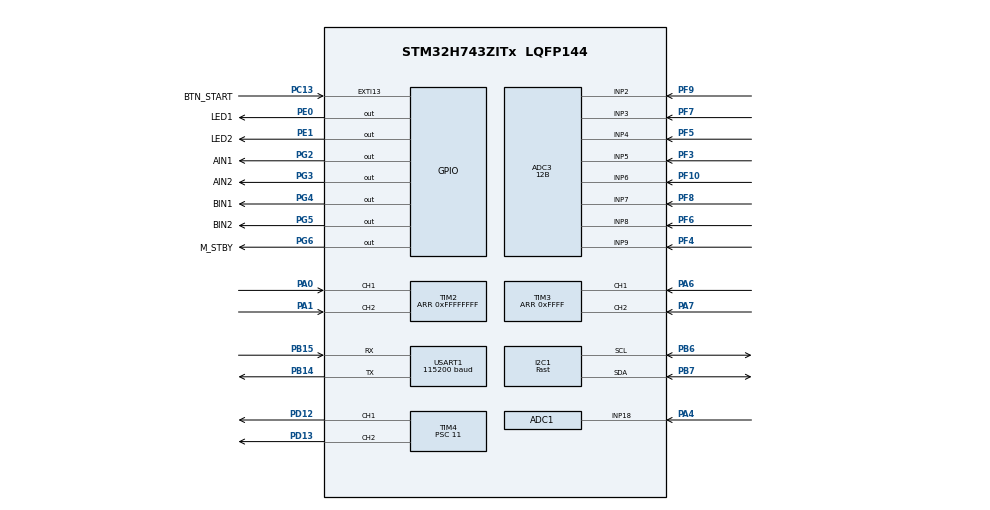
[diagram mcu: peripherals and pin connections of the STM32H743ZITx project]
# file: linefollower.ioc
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ADC1.Channel-1\#ChannelRegularConversion=ADC_CHANNEL_18
ADC1.NbrOfConversionFlag=1
ADC1.OffsetNumber-1\#ChannelRegularConversion=ADC_OFFSET_NONE
ADC1.OffsetSignedSaturation-1\#ChannelRegularConversion=DISABLE
ADC1.Rank-1\#ChannelRegularConversion=1
ADC1.Resolution=ADC_RESOLUTION_12B
ADC1.SamplingTime-1\#ChannelRegularConversion=ADC_SAMPLETIME_810CYCLES_5
ADC1.master=1
ADC3.Channel-0\#ChannelRegularConversion=ADC_CHANNEL_5
ADC3.Channel-1\#ChannelRegularConversion=ADC_CHANNEL_9
ADC3.Channel-2\#ChannelRegularConversion=ADC_CHANNEL_4
ADC3.Channel-3\#ChannelRegularConversion=ADC_CHANNEL_8
ADC3.Channel-4\#ChannelRegularConversion=ADC_CHANNEL_3
ADC3.Channel-5\#ChannelRegularConversion=ADC_CHANNEL_7
ADC3.Channel-6\#ChannelRegularConversion=ADC_CHANNEL_2
ADC3.Channel-7\#ChannelRegularConversion=ADC_CHANNEL_6
ADC3.ConversionDataManagement=ADC_CONVERSIONDATA_DMA_CIRCULAR
ADC3.EOCSelection=ADC_EOC_SEQ_CONV
ADC3.ExternalTrigConv=ADC_EXTERNALTRIG_T6_TRGO
ADC3.NbrOfConversion=8
ADC3.NbrOfConversionFlag=1
ADC3.OffsetNumber-0\#ChannelRegularConversion=ADC_OFFSET_NONE
ADC3.OffsetNumber-1\#ChannelRegularConversion=ADC_OFFSET_NONE
ADC3.OffsetNumber-2\#ChannelRegularConversion=ADC_OFFSET_NONE
ADC3.OffsetNumber-3\#ChannelRegularConversion=ADC_OFFSET_NONE
ADC3.OffsetNumber-4\#ChannelRegularConversion=ADC_OFFSET_NONE
ADC3.OffsetNumber-5\#ChannelRegularConversion=ADC_OFFSET_NONE
ADC3.OffsetNumber-6\#ChannelRegularConversion=ADC_OFFSET_NONE
ADC3.OffsetNumber-7\#ChannelRegularConversion=ADC_OFFSET_NONE
ADC3.OffsetSignedSaturation-0\#ChannelRegularConversion=DISABLE
ADC3.Rank-0\#ChannelRegularConversion=1
ADC3.Rank-1\#ChannelRegularConversion=2
ADC3.Rank-2\#ChannelRegularConversion=3
ADC3.Rank-3\#ChannelRegularConversion=4
ADC3.Rank-4\#ChannelRegularConversion=5
ADC3.Rank-5\#ChannelRegularConversion=6
ADC3.Rank-6\#ChannelRegularConversion=7
ADC3.Rank-7\#ChannelRegularConversion=8
ADC3.Resolution=ADC_RESOLUTION_12B
ADC3.SamplingTime-0\#ChannelRegularConversion=ADC_SAMPLETIME_387CYCLES_5
ADC3.SamplingTime-1\#ChannelRegularConversion=ADC_SAMPLETIME_387CYCLES_5
ADC3.SamplingTime-2\#ChannelRegularConversion=ADC_SAMPLETIME_387CYCLES_5
ADC3.SamplingTime-3\#ChannelRegularConversion=ADC_SAMPLETIME_387CYCLES_5
ADC3.SamplingTime-4\#ChannelRegularConversion=ADC_SAMPLETIME_387CYCLES_5
ADC3.SamplingTime-5\#ChannelRegularConversion=ADC_SAMPLETIME_387CYCLES_5
ADC3.SamplingTime-6\#ChannelRegularConversion=ADC_SAMPLETIME_387CYCLES_5
ADC3.SamplingTime-7\#ChannelRegularConversion=ADC_SAMPLETIME_387CYCLES_5
Bdma.ADC3.0.Direction=DMA_PERIPH_TO_MEMORY
Bdma.ADC3.0.EventEnable=DISABLE
Bdma.ADC3.0.Instance=BDMA_Channel0
Bdma.ADC3.0.MemDataAlignment=DMA_MDATAALIGN_HALFWORD
Bdma.ADC3.0.MemInc=DMA_MINC_ENABLE
Bdma.ADC3.0.Mode=DMA_CIRCULAR
Bdma.ADC3.0.PeriphDataAlignment=DMA_PDATAALIGN_HALFWORD
Bdma.ADC3.0.PeriphInc=DMA_PINC_DISABLE
Bdma.ADC3.0.Polarity=HAL_DMAMUX_REQ_GEN_RISING
Bdma.ADC3.0.Priority=DMA_PRIORITY_LOW
Bdma.ADC3.0.RequestNumber=1
Bdma.ADC3.0.SignalID=NONE
Bdma.ADC3.0.SyncEnable=DISABLE
Bdma.ADC3.0.SyncPolarity=HAL_DMAMUX_SYNC_NO_EVENT
Bdma.ADC3.0.SyncRequestNumber=1
Bdma.ADC3.0.SyncSignalID=NONE
Bdma.Request0=ADC3
Bdma.RequestsNb=1
CORTEX_M7.AccessPermission_S-Cortex_Memory_Protection_Unit_Region1_Settings_S=MPU_REGION_FULL_ACCESS
CORTEX_M7.AccessPermission_Spec=MPU_REGION_NO_ACCESS
CORTEX_M7.BaseAddress_S-Cortex_Memory_Protection_Unit_Region1_Settings_S=0x38000000
CORTEX_M7.BaseAddress_Spec=0x0
CORTEX_M7.CPU_DCache=Enabled
CORTEX_M7.CPU_ICache=Enabled
CORTEX_M7.DisableExec_S-Cortex_Memory_Protection_Unit_Region1_Settings_S=MPU_INSTRUCTION_ACCESS_DISABLE
CORTEX_M7.DisableExec_Spec=MPU_INSTRUCTION_ACCESS_ENABLE
CORTEX_M7.Enable_S-Cortex_Memory_Protection_Unit_Region1_Settings_S=MPU_REGION_ENABLE
CORTEX_M7.IsShareable_Spec=MPU_ACCESS_NOT_SHAREABLE
CORTEX_M7.Size_S-Cortex_Memory_Protection_Unit_Region1_Settings_S=MPU_REGION_SIZE_64KB
CORTEX_M7.Size_Spec=MPU_REGION_SIZE_4GB
CORTEX_M7.SubRegionDisable_Spec=0x87
CORTEX_M7.TypeExtField_S-Cortex_Memory_Protection_Unit_Region1_Settings_S=MPU_TEX_LEVEL1
CORTEX_M7.TypeExtField_Spec=MPU_TEX_LEVEL0
CORTEX_M7.default_mode_Activation=1
Dma.Request0=USART1_RX
Dma.Request1=USART1_TX
Dma.USART1_RX.0.Direction=DMA_PERIPH_TO_MEMORY
Dma.USART1_RX.0.EventEnable=DISABLE
Dma.USART1_RX.0.FIFOMode=DMA_FIFOMODE_DISABLE
Dma.USART1_RX.0.Instance=DMA1_Stream0
Dma.USART1_RX.0.MemDataAlignment=DMA_MDATAALIGN_BYTE
Dma.USART1_RX.0.MemInc=DMA_MINC_ENABLE
Dma.USART1_RX.0.Mode=DMA_CIRCULAR
Dma.USART1_RX.0.PeriphDataAlignment=DMA_PDATAALIGN_BYTE
Dma.USART1_RX.0.PeriphInc=DMA_PINC_DISABLE
Dma.USART1_RX.0.Polarity=HAL_DMAMUX_REQ_GEN_RISING
Dma.USART1_RX.0.Priority=DMA_PRIORITY_LOW
Dma.USART1_RX.0.RequestNumber=1
Dma.USART1_RX.0.SignalID=NONE
Dma.USART1_RX.0.SyncEnable=DISABLE
Dma.USART1_RX.0.SyncPolarity=HAL_DMAMUX_SYNC_NO_EVENT
Dma.USART1_RX.0.SyncRequestNumber=1
Dma.USART1_RX.0.SyncSignalID=NONE
Dma.USART1_TX.1.Direction=DMA_MEMORY_TO_PERIPH
Dma.USART1_TX.1.EventEnable=DISABLE
Dma.USART1_TX.1.FIFOMode=DMA_FIFOMODE_DISABLE
Dma.USART1_TX.1.Instance=DMA1_Stream1
Dma.USART1_TX.1.MemDataAlignment=DMA_MDATAALIGN_BYTE
Dma.USART1_TX.1.MemInc=DMA_MINC_ENABLE
Dma.USART1_TX.1.Mode=DMA_NORMAL
Dma.USART1_TX.1.PeriphDataAlignment=DMA_PDATAALIGN_BYTE
Dma.USART1_TX.1.PeriphInc=DMA_PINC_DISABLE
Dma.USART1_TX.1.Polarity=HAL_DMAMUX_REQ_GEN_RISING
Dma.USART1_TX.1.Priority=DMA_PRIORITY_LOW
Dma.USART1_TX.1.RequestNumber=1
Dma.USART1_TX.1.SignalID=NONE
Dma.USART1_TX.1.SyncEnable=DISABLE
Dma.USART1_TX.1.SyncPolarity=HAL_DMAMUX_SYNC_NO_EVENT
Dma.USART1_TX.1.SyncRequestNumber=1
Dma.USART1_TX.1.SyncSignalID=NONE
I2C1.I2C_Rise_Time=100
I2C1.I2C_Speed_Mode=I2C_Fast
I2C1.Timing=0x10B01F67
Mcu.Family=STM32H7
Mcu.Name=STM32H743ZITx
Mcu.Package=LQFP144
NVIC.BDMA_Channel0_IRQn=true\:2\:0\:true\:false\:true\:false\:true\:true
NVIC.DMA1_Stream0_IRQn=true\:5\:0\:true\:false\:true\:false\:true\:true
NVIC.DMA1_Stream1_IRQn=true\:5\:0\:true\:false\:true\:false\:true\:true
NVIC.EXTI15_10_IRQn=true\:7\:0\:true\:false\:true\:true\:true\:true
NVIC.I2C1_ER_IRQn=true\:6\:0\:true\:false\:true\:true\:true\:true
NVIC.I2C1_EV_IRQn=true\:6\:0\:true\:false\:true\:true\:true\:true
NVIC.PriorityGroup=NVIC_PRIORITYGROUP_4
NVIC.TIM6_DAC_IRQn=true\:1\:0\:true\:false\:true\:true\:true\:true
NVIC.USART1_IRQn=true\:5\:0\:true\:false\:true\:true\:true\:true
PA0.Signal=S_TIM2_CH1_ETR
PA1.Signal=S_TIM2_CH2
PA13\ (JTMS/SWDIO).Mode=Trace_Asynchronous_SW
PA13\ (JTMS/SWDIO).Signal=DEBUG_JTMS-SWDIO
PA14\ (JTCK/SWCLK).Mode=Trace_Asynchronous_SW
PA14\ (JTCK/SWCLK).Signal=DEBUG_JTCK-SWCLK
PA4.Signal=ADCx_INP18
PA6.Signal=S_TIM3_CH1
PA7.Signal=S_TIM3_CH2
PB14.Mode=Asynchronous
PB14.Signal=USART1_TX
PB15.Mode=Asynchronous
PB15.Signal=USART1_RX
PB3\ (JTDO/TRACESWO).Mode=Trace_Asynchronous_SW
PB3\ (JTDO/TRACESWO).Signal=DEBUG_JTDO-SWO
PB6.Mode=I2C
PB6.Signal=I2C1_SCL
PB7.Mode=I2C
PB7.Signal=I2C1_SDA
PC13.GPIO_Label=BTN_START
PC13.GPIO_ModeDefaultEXTI=GPIO_MODE_IT_FALLING
PC13.GPIO_PuPd=GPIO_PULLUP
PC13.Signal=GPXTI13
PD12.Signal=S_TIM4_CH1
PD13.Signal=S_TIM4_CH2
PE0.GPIO_Label=LED1
PE0.Signal=GPIO_Output
PE1.GPIO_Label=LED2
PE1.Signal=GPIO_Output
PF10.Mode=IN6-Single-Ended
PF10.Signal=ADC3_INP6
PF3.Mode=IN5-Single-Ended
PF3.Signal=ADC3_INP5
PF4.Mode=IN9-Single-Ended
PF4.Signal=ADC3_INP9
PF5.Mode=IN4-Single-Ended
PF5.Signal=ADC3_INP4
PF6.Mode=IN8-Single-Ended
PF6.Signal=ADC3_INP8
PF7.Mode=IN3-Single-Ended
PF7.Signal=ADC3_INP3
PF8.Mode=IN7-Single-Ended
PF8.Signal=ADC3_INP7
PF9.Mode=IN2-Single-Ended
PF9.Signal=ADC3_INP2
PG2.GPIO_Label=AIN1
PG2.Signal=GPIO_Output
PG3.GPIO_Label=AIN2
PG3.Signal=GPIO_Output
PG4.GPIO_Label=BIN1
PG4.Signal=GPIO_Output
PG5.GPIO_Label=BIN2
PG5.Signal=GPIO_Output
PG6.GPIO_Label=M_STBY
PG6.Signal=GPIO_Output
PH0-OSC_IN\ (PH0).Mode=HSE-External-Oscillator
PH0-OSC_IN\ (PH0).Signal=RCC_OSC_IN
PH1-OSC_OUT\ (PH1).Mode=HSE-External-Oscillator
PH1-OSC_OUT\ (PH1).Signal=RCC_OSC_OUT
ProjectManager.HeapSize=0x200
ProjectManager.StackSize=0x400
ProjectManager.TargetToolchain=STM32CubeIDE
RCC.ADCFreq_Value=36000000
RCC.APB1Freq_Value=120000000
RCC.APB2Freq_Value=120000000
RCC.APB3Freq_Value=120000000
RCC.APB4Freq_Value=120000000
RCC.CortexFreq_Value=480000000
RCC.D1PPRE=RCC_APB3_DIV2
RCC.D2PPRE1=RCC_APB1_DIV2
RCC.D2PPRE2=RCC_APB2_DIV2
RCC.D3PPRE=RCC_APB4_DIV2
RCC.DIVM1=5
RCC.DIVM2=5
RCC.DIVN1=192
RCC.DIVN2=72
RCC.DIVP2=10
RCC.HCLKFreq_Value=240000000
RCC.HPRE=RCC_HCLK_DIV2
RCC.HSE_VALUE=25000000
RCC.PLL2FRACN=0
RCC.PLL3FRACN=0
RCC.PLLFRACN=0
RCC.PLLSourceVirtual=RCC_PLLSOURCE_HSE
RCC.SYSCLKFreq_VALUE=480000000
RCC.SYSCLKSource=RCC_SYSCLKSOURCE_PLLCLK
RCC.USBFreq_Value=480000000
SH.ADCx_INP18.0=ADC1_INP18,IN18-Single-Ended
SH.S_TIM2_CH1_ETR.0=TIM2_CH1,Encoder_Interface
SH.S_TIM2_CH2.0=TIM2_CH2,Encoder_Interface
SH.S_TIM3_CH1.0=TIM3_CH1,Encoder_Interface
SH.S_TIM3_CH2.0=TIM3_CH2,Encoder_Interface
SH.S_TIM4_CH1.0=TIM4_CH1,PWM Generation1 CH1
SH.S_TIM4_CH2.0=TIM4_CH2,PWM Generation2 CH2
TIM2.EncoderMode=TIM_ENCODERMODE_TI12
TIM2.IC1Filter=6
TIM2.IC2Filter=6
TIM2.Period=0xFFFFFFFF
TIM3.EncoderMode=TIM_ENCODERMODE_TI12
TIM3.IC1Filter=6
TIM3.IC2Filter=6
TIM3.Period=0xFFFF
TIM4.AutoReloadPreload=TIM_AUTORELOAD_PRELOAD_ENABLE
TIM4.Channel-PWM\ Generation1\ CH1=TIM_CHANNEL_1
TIM4.Channel-PWM\ Generation2\ CH2=TIM_CHANNEL_2
TIM4.OCFastMode_PWM-PWM\ Generation1\ CH1=TIM_OCFAST_ENABLE
TIM4.OCFastMode_PWM-PWM\ Generation2\ CH2=TIM_OCFAST_ENABLE
TIM4.Period=999
TIM4.Prescaler=11
TIM6.Period=999
TIM6.Prescaler=239
TIM6.TIM_MasterOutputTrigger=TIM_TRGO_UPDATE
USART1.BaudRate=115200
USART1.VirtualMode-Asynchronous=VM_ASYNC
VP_MEMORYMAP_VS_MEMORYMAP.Mode=CurAppReg
VP_TIM4_VS_ClockSourceINT.Mode=Internal
VP_TIM6_VS_ClockSourceINT.Mode=Enable_Timer
board=custom

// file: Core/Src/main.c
/* USER CODE BEGIN Header */
/**
  ******************************************************************************
  * @file           : main.c
  * @brief          : Main program body
  ******************************************************************************
  * @attention
  *
  * Copyright (c) 2026 STMicroelectronics.
  * All rights reserved.
  *
  * This software is licensed under terms that can be found in the LICENSE file
  * in the root directory of this software component.
  * If no LICENSE file comes with this software, it is provided AS-IS.
  *
  ******************************************************************************
  */
/* USER CODE END Header */
#include "main.h"
#include "adc.h"
#include "bdma.h"
#include "dma.h"
#include "i2c.h"
#include "memorymap.h"
#include "tim.h"
#include "usart.h"
#include "gpio.h"

/* USER CODE BEGIN PV */
/* ADC3 results, SENS1..SENS8. Stored at the start of RAM_D3 (0x38000000),
   the only RAM the BDMA can reach. MPU makes this area non-cacheable. */
#define ADC3_BUF ((volatile uint16_t *)0x38000000UL)
/* USER CODE END PV */

void SystemClock_Config(void);
void PeriphCommonClock_Config(void);
static void MPU_Config(void);

int main(void)
{

  /* MPU Configuration--------------------------------------------------------*/
  MPU_Config();

  /* Enable the CPU Cache */

  /* Enable I-Cache---------------------------------------------------------*/
  SCB_EnableICache();

  /* Enable D-Cache---------------------------------------------------------*/
  SCB_EnableDCache();

  /* MCU Configuration--------------------------------------------------------*/

  /* Reset of all peripherals, Initializes the Flash interface and the Systick. */
  HAL_Init();

  /* Configure the system clock */
  SystemClock_Config();

  /* Configure the peripherals common clocks */
  PeriphCommonClock_Config();

  /* Initialize all configured peripherals */
  MX_GPIO_Init();
  MX_DMA_Init();
  MX_BDMA_Init();
  MX_USART1_UART_Init();
  MX_ADC1_Init();
  MX_I2C1_Init();
  MX_TIM2_Init();
  MX_TIM3_Init();
  MX_TIM4_Init();
  MX_ADC3_Init();
  MX_TIM6_Init();
  /* USER CODE BEGIN 2 */
  HAL_ADCEx_Calibration_Start(&hadc3, ADC_CALIB_OFFSET, ADC_SINGLE_ENDED); /* calibrate once at start-up */
  HAL_ADC_Start_DMA(&hadc3, (uint32_t *)ADC3_BUF, 8);  /* arm ADC3: 8 results per scan, BDMA circular */
  HAL_TIM_Base_Start_IT(&htim6);                        /* start the 1 kHz tick; it also triggers each ADC3 scan */
  /* USER CODE END 2 */

  /* Infinite loop */
  while (1)
  {

  }
}

void SystemClock_Config(void)
{
  RCC_OscInitTypeDef RCC_OscInitStruct = {0};
  RCC_ClkInitTypeDef RCC_ClkInitStruct = {0};

  /** Supply configuration update enable
  */
  HAL_PWREx_ConfigSupply(PWR_LDO_SUPPLY);

  /** Configure the main internal regulator output voltage
  */
  __HAL_PWR_VOLTAGESCALING_CONFIG(PWR_REGULATOR_VOLTAGE_SCALE0);

  while(!__HAL_PWR_GET_FLAG(PWR_FLAG_VOSRDY)) {}

  /** Initializes the RCC Oscillators according to the specified parameters
  * in the RCC_OscInitTypeDef structure.
  */
  RCC_OscInitStruct.OscillatorType = RCC_OSCILLATORTYPE_HSE;
  RCC_OscInitStruct.HSEState = RCC_HSE_ON;
  RCC_OscInitStruct.PLL.PLLState = RCC_PLL_ON;
  RCC_OscInitStruct.PLL.PLLSource = RCC_PLLSOURCE_HSE;
  RCC_OscInitStruct.PLL.PLLM = 5;
  RCC_OscInitStruct.PLL.PLLN = 192;
  RCC_OscInitStruct.PLL.PLLP = 2;
  RCC_OscInitStruct.PLL.PLLQ = 2;
  RCC_OscInitStruct.PLL.PLLR = 2;
  RCC_OscInitStruct.PLL.PLLRGE = RCC_PLL1VCIRANGE_2;
  RCC_OscInitStruct.PLL.PLLVCOSEL = RCC_PLL1VCOWIDE;
  RCC_OscInitStruct.PLL.PLLFRACN = 0;
  if (HAL_RCC_OscConfig(&RCC_OscInitStruct) != HAL_OK)
  {
    Error_Handler();
  }

  /** Initializes the CPU, AHB and APB buses clocks
  */
  RCC_ClkInitStruct.ClockType = RCC_CLOCKTYPE_HCLK|RCC_CLOCKTYPE_SYSCLK
                              |RCC_CLOCKTYPE_PCLK1|RCC_CLOCKTYPE_PCLK2
                              |RCC_CLOCKTYPE_D3PCLK1|RCC_CLOCKTYPE_D1PCLK1;
  RCC_ClkInitStruct.SYSCLKSource = RCC_SYSCLKSOURCE_PLLCLK;
  RCC_ClkInitStruct.SYSCLKDivider = RCC_SYSCLK_DIV1;
  RCC_ClkInitStruct.AHBCLKDivider = RCC_HCLK_DIV2;
  RCC_ClkInitStruct.APB3CLKDivider = RCC_APB3_DIV2;
  RCC_ClkInitStruct.APB1CLKDivider = RCC_APB1_DIV2;
  RCC_ClkInitStruct.APB2CLKDivider = RCC_APB2_DIV2;
  RCC_ClkInitStruct.APB4CLKDivider = RCC_APB4_DIV2;

  if (HAL_RCC_ClockConfig(&RCC_ClkInitStruct, FLASH_LATENCY_4) != HAL_OK)
  {
    Error_Handler();
  }
}

void PeriphCommonClock_Config(void)
{
  RCC_PeriphCLKInitTypeDef PeriphClkInitStruct = {0};

  /** Initializes the peripherals clock
  */
  PeriphClkInitStruct.PeriphClockSelection = RCC_PERIPHCLK_ADC;
  PeriphClkInitStruct.PLL2.PLL2M = 5;
  PeriphClkInitStruct.PLL2.PLL2N = 72;
  PeriphClkInitStruct.PLL2.PLL2P = 10;
  PeriphClkInitStruct.PLL2.PLL2Q = 2;
  PeriphClkInitStruct.PLL2.PLL2R = 2;
  PeriphClkInitStruct.PLL2.PLL2RGE = RCC_PLL2VCIRANGE_2;
  PeriphClkInitStruct.PLL2.PLL2VCOSEL = RCC_PLL2VCOWIDE;
  PeriphClkInitStruct.PLL2.PLL2FRACN = 0;
  PeriphClkInitStruct.AdcClockSelection = RCC_ADCCLKSOURCE_PLL2;
  if (HAL_RCCEx_PeriphCLKConfig(&PeriphClkInitStruct) != HAL_OK)
  {
    Error_Handler();
  }
}

 /* MPU Configuration */

void MPU_Config(void)
{
  MPU_Region_InitTypeDef MPU_InitStruct = {0};

  /* Disables the MPU */
  HAL_MPU_Disable();

  /** Initializes and configures the Region and the memory to be protected
  */
  MPU_InitStruct.Enable = MPU_REGION_ENABLE;
  MPU_InitStruct.Number = MPU_REGION_NUMBER0;
  MPU_InitStruct.BaseAddress = 0x0;
  MPU_InitStruct.Size = MPU_REGION_SIZE_4GB;
  MPU_InitStruct.SubRegionDisable = 0x87;
  MPU_InitStruct.TypeExtField = MPU_TEX_LEVEL0;
  MPU_InitStruct.AccessPermission = MPU_REGION_NO_ACCESS;
  MPU_InitStruct.DisableExec = MPU_INSTRUCTION_ACCESS_ENABLE;
  MPU_InitStruct.IsShareable = MPU_ACCESS_NOT_SHAREABLE;
  MPU_InitStruct.IsCacheable = MPU_ACCESS_NOT_CACHEABLE;
  MPU_InitStruct.IsBufferable = MPU_ACCESS_NOT_BUFFERABLE;

  HAL_MPU_ConfigRegion(&MPU_InitStruct);

  /** Initializes and configures the Region and the memory to be protected
  */
  MPU_InitStruct.Number = MPU_REGION_NUMBER1;
  MPU_InitStruct.BaseAddress = 0x38000000;
  MPU_InitStruct.Size = MPU_REGION_SIZE_64KB;
  MPU_InitStruct.SubRegionDisable = 0x0;
  MPU_InitStruct.TypeExtField = MPU_TEX_LEVEL1;
  MPU_InitStruct.AccessPermission = MPU_REGION_FULL_ACCESS;
  MPU_InitStruct.DisableExec = MPU_INSTRUCTION_ACCESS_DISABLE;

  HAL_MPU_ConfigRegion(&MPU_InitStruct);
  /* Enables the MPU */
  HAL_MPU_Enable(MPU_PRIVILEGED_DEFAULT);

}

void Error_Handler(void)
{
  __disable_irq();
  while (1)
  {
  }
}
